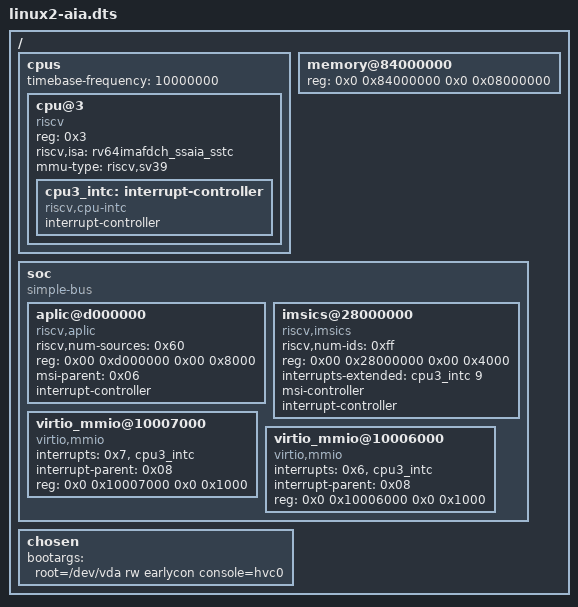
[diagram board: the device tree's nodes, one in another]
/dts-v1/;

/ {
	#address-cells = <0x2>;
	#size-cells = <0x2>;

	cpus {
		#address-cells = <0x1>;
		#size-cells = <0x0>;
		timebase-frequency = <10000000>;
		cpu@3 {
			device_type = "cpu";
			reg = <0x3>;
			status = "okay";
			compatible = "riscv";
			riscv,isa = "rv64imafdch_ssaia_sstc";
			mmu-type = "riscv,sv39";

			cpu3_intc: interrupt-controller {
				#interrupt-cells = <0x1>;
				interrupt-controller;
				compatible = "riscv,cpu-intc";
			};
		};

	};

	memory@84000000 {
		device_type = "memory";
		reg = <0x0 0x84000000 0x0 0x08000000>;
	};
soc{
	#address-cells = <0x02>;
	#size-cells = <0x02>;
	compatible = "simple-bus";
	ranges;
		
	aplic@d000000 {
		phandle = <0x08>;
		riscv,num-sources = <0x60>;
		reg = <0x00 0xd000000 0x00 0x8000>;
		msi-parent = <0x06>;
		interrupt-controller;
		#interrupt-cells = <0x02>;
		compatible = "riscv,aplic";
	};

	imsics@28000000 {
		phandle = <0x06>;
		riscv,num-ids = <0xff>;
		reg = <0x00 0x28000000 0x00 0x4000>;
		interrupts-extended = <
			&cpu3_intc 9
		>;
		msi-controller;
		interrupt-controller;
		#interrupt-cells = <0x00>;
		compatible = "riscv,imsics";
	};

	virtio_mmio@10007000 {
		interrupts = <0x7 &cpu3_intc>;
		interrupt-parent = <0x08>;
		reg = <0x0 0x10007000 0x0 0x1000>;
		compatible = "virtio,mmio";
	};

	virtio_mmio@10006000 {
		interrupts = <0x6 &cpu3_intc>;
		interrupt-parent = <0x08>;
		reg = <0x0 0x10006000 0x0 0x1000>;
		compatible = "virtio,mmio";
	};

};

	chosen {
		bootargs = "root=/dev/vda rw earlycon console=hvc0";
	};
};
